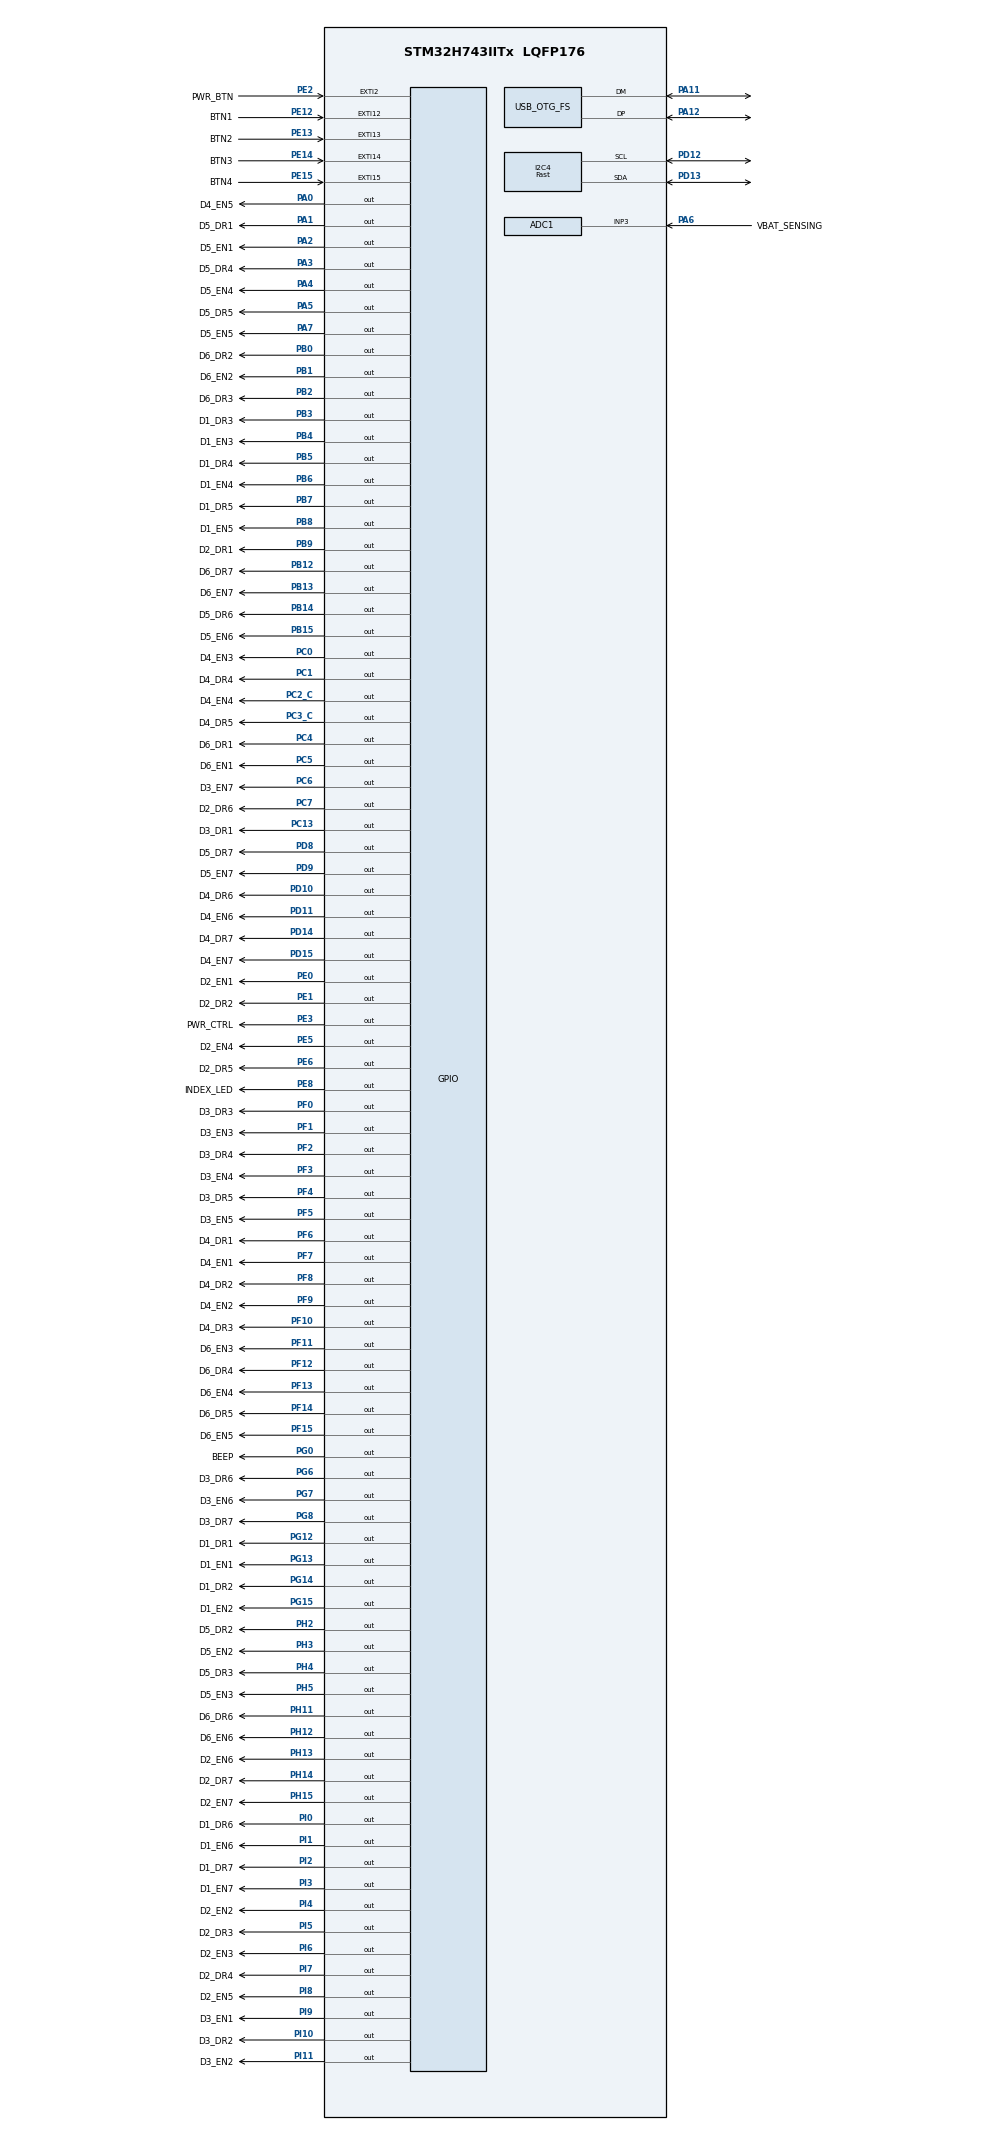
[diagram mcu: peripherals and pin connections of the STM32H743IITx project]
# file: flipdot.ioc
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ADC1.Channel-0\#ChannelRegularConversion=ADC_CHANNEL_3
ADC1.NbrOfConversionFlag=1
ADC1.OffsetNumber-0\#ChannelRegularConversion=ADC_OFFSET_NONE
ADC1.OffsetSignedSaturation-0\#ChannelRegularConversion=DISABLE
ADC1.Rank-0\#ChannelRegularConversion=1
ADC1.SamplingTime-0\#ChannelRegularConversion=ADC_SAMPLETIME_810CYCLES_5
ADC1.master=1
CORTEX_M7.AccessPermission_S-Cortex_Memory_Protection_Unit_Region1_Settings_S=MPU_REGION_FULL_ACCESS
CORTEX_M7.AccessPermission_Spec=MPU_REGION_FULL_ACCESS
CORTEX_M7.BaseAddress_S-Cortex_Memory_Protection_Unit_Region1_Settings_S=0x0
CORTEX_M7.BaseAddress_Spec=0x24000000
CORTEX_M7.Enable_S-Cortex_Memory_Protection_Unit_Region1_Settings_S=MPU_REGION_ENABLE
CORTEX_M7.IsCacheable_Spec=MPU_ACCESS_CACHEABLE
CORTEX_M7.Size_S-Cortex_Memory_Protection_Unit_Region1_Settings_S=MPU_REGION_SIZE_32MB
CORTEX_M7.Size_Spec=MPU_REGION_SIZE_512KB
CORTEX_M7.SubRegionDisable_Spec=0x00
CORTEX_M7.default_mode_Activation=1
Dma.ADC1.0.Direction=DMA_PERIPH_TO_MEMORY
Dma.ADC1.0.EventEnable=DISABLE
Dma.ADC1.0.FIFOMode=DMA_FIFOMODE_DISABLE
Dma.ADC1.0.Instance=DMA1_Stream0
Dma.ADC1.0.MemDataAlignment=DMA_MDATAALIGN_HALFWORD
Dma.ADC1.0.MemInc=DMA_MINC_ENABLE
Dma.ADC1.0.Mode=DMA_CIRCULAR
Dma.ADC1.0.PeriphDataAlignment=DMA_PDATAALIGN_HALFWORD
Dma.ADC1.0.PeriphInc=DMA_PINC_DISABLE
Dma.ADC1.0.Polarity=HAL_DMAMUX_REQ_GEN_RISING
Dma.ADC1.0.Priority=DMA_PRIORITY_LOW
Dma.ADC1.0.RequestNumber=1
Dma.ADC1.0.SignalID=NONE
Dma.ADC1.0.SyncEnable=DISABLE
Dma.ADC1.0.SyncPolarity=HAL_DMAMUX_SYNC_NO_EVENT
Dma.ADC1.0.SyncRequestNumber=1
Dma.ADC1.0.SyncSignalID=NONE
Dma.Request0=ADC1
FREERTOS.Queues01=button_queue,16,uint16_t,0,Dynamic,NULL,NULL
FREERTOS.Tasks01=defaultTask,24,256,StartDefaultTask,Default,NULL,Dynamic,NULL,NULL;buttonTask,24,1024,button_task,Default,NULL,Dynamic,NULL,NULL
FREERTOS.configUSE_NEWLIB_REENTRANT=1
I2C4.I2C_Speed_Mode=I2C_Fast
I2C4.Timing=0x00B03FDB
Mcu.Family=STM32H7
Mcu.Name=STM32H743IITx
Mcu.Package=LQFP176
NVIC.ADC_IRQn=true\:5\:0\:false\:false\:true\:true\:true\:true\:true
NVIC.DMA1_Stream0_IRQn=true\:5\:0\:false\:false\:true\:true\:false\:true\:true
NVIC.EXTI15_10_IRQn=true\:5\:0\:false\:false\:true\:true\:true\:true\:true
NVIC.EXTI2_IRQn=true\:5\:0\:false\:false\:true\:true\:true\:true\:true
NVIC.OTG_FS_IRQn=true\:5\:0\:false\:false\:true\:true\:false\:true\:true
NVIC.PriorityGroup=NVIC_PRIORITYGROUP_4
NVIC.TIM2_IRQn=true\:15\:0\:false\:false\:true\:false\:false\:true\:true
NVIC.TimeBase=TIM2_IRQn
NVIC.TimeBaseIP=TIM2
PA0.GPIO_Label=D4_EN5
PA0.GPIO_PuPd=GPIO_PULLDOWN
PA0.GPIO_Speed=GPIO_SPEED_FREQ_VERY_HIGH
PA0.Signal=GPIO_Output
PA1.GPIO_Label=D5_DR1
PA1.GPIO_PuPd=GPIO_PULLDOWN
PA1.GPIO_Speed=GPIO_SPEED_FREQ_VERY_HIGH
PA1.Signal=GPIO_Output
PA11.Mode=Device_Only
PA11.Signal=USB_OTG_FS_DM
PA12.Mode=Device_Only
PA12.Signal=USB_OTG_FS_DP
PA13\ (JTMS/SWDIO).Mode=Serial_Wire
PA13\ (JTMS/SWDIO).Signal=DEBUG_JTMS-SWDIO
PA14\ (JTCK/SWCLK).Mode=Serial_Wire
PA14\ (JTCK/SWCLK).Signal=DEBUG_JTCK-SWCLK
PA2.GPIO_Label=D5_EN1
PA2.GPIO_PuPd=GPIO_PULLDOWN
PA2.GPIO_Speed=GPIO_SPEED_FREQ_VERY_HIGH
PA2.Signal=GPIO_Output
PA3.GPIO_Label=D5_DR4
PA3.GPIO_PuPd=GPIO_PULLDOWN
PA3.GPIO_Speed=GPIO_SPEED_FREQ_VERY_HIGH
PA3.Signal=GPIO_Output
PA4.GPIO_Label=D5_EN4
PA4.GPIO_PuPd=GPIO_PULLDOWN
PA4.GPIO_Speed=GPIO_SPEED_FREQ_VERY_HIGH
PA4.Signal=GPIO_Output
PA5.GPIO_Label=D5_DR5
PA5.GPIO_PuPd=GPIO_PULLDOWN
PA5.GPIO_Speed=GPIO_SPEED_FREQ_VERY_HIGH
PA5.Signal=GPIO_Output
PA6.GPIO_Label=VBAT_SENSING
PA6.Signal=ADCx_INP3
PA7.GPIO_Label=D5_EN5
PA7.GPIO_PuPd=GPIO_PULLDOWN
PA7.GPIO_Speed=GPIO_SPEED_FREQ_VERY_HIGH
PA7.Signal=GPIO_Output
PB0.GPIO_Label=D6_DR2
PB0.GPIO_PuPd=GPIO_PULLDOWN
PB0.GPIO_Speed=GPIO_SPEED_FREQ_VERY_HIGH
PB0.Signal=GPIO_Output
PB1.GPIO_Label=D6_EN2
PB1.GPIO_PuPd=GPIO_PULLDOWN
PB1.GPIO_Speed=GPIO_SPEED_FREQ_VERY_HIGH
PB1.Signal=GPIO_Output
PB12.GPIO_Label=D6_DR7
PB12.GPIO_PuPd=GPIO_PULLDOWN
PB12.GPIO_Speed=GPIO_SPEED_FREQ_VERY_HIGH
PB12.Signal=GPIO_Output
PB13.GPIO_Label=D6_EN7
PB13.GPIO_PuPd=GPIO_PULLDOWN
PB13.GPIO_Speed=GPIO_SPEED_FREQ_VERY_HIGH
PB13.Signal=GPIO_Output
PB14.GPIO_Label=D5_DR6
PB14.GPIO_PuPd=GPIO_PULLDOWN
PB14.GPIO_Speed=GPIO_SPEED_FREQ_VERY_HIGH
PB14.Signal=GPIO_Output
PB15.GPIO_Label=D5_EN6
PB15.GPIO_PuPd=GPIO_PULLDOWN
PB15.GPIO_Speed=GPIO_SPEED_FREQ_VERY_HIGH
PB15.Signal=GPIO_Output
PB2.GPIO_Label=D6_DR3
PB2.GPIO_PuPd=GPIO_PULLDOWN
PB2.GPIO_Speed=GPIO_SPEED_FREQ_VERY_HIGH
PB2.Signal=GPIO_Output
PB3\ (JTDO/TRACESWO).GPIO_Label=D1_DR3
PB3\ (JTDO/TRACESWO).GPIO_PuPd=GPIO_PULLDOWN
PB3\ (JTDO/TRACESWO).GPIO_Speed=GPIO_SPEED_FREQ_VERY_HIGH
PB3\ (JTDO/TRACESWO).Signal=GPIO_Output
PB4\ (NJTRST).GPIO_Label=D1_EN3
PB4\ (NJTRST).GPIO_PuPd=GPIO_PULLDOWN
PB4\ (NJTRST).GPIO_Speed=GPIO_SPEED_FREQ_VERY_HIGH
PB4\ (NJTRST).Signal=GPIO_Output
PB5.GPIO_Label=D1_DR4
PB5.GPIO_PuPd=GPIO_PULLDOWN
PB5.GPIO_Speed=GPIO_SPEED_FREQ_VERY_HIGH
PB5.Signal=GPIO_Output
PB6.GPIO_Label=D1_EN4
PB6.GPIO_PuPd=GPIO_PULLDOWN
PB6.GPIO_Speed=GPIO_SPEED_FREQ_VERY_HIGH
PB6.Signal=GPIO_Output
PB7.GPIO_Label=D1_DR5
PB7.GPIO_PuPd=GPIO_PULLDOWN
PB7.GPIO_Speed=GPIO_SPEED_FREQ_VERY_HIGH
PB7.Signal=GPIO_Output
PB8.GPIO_Label=D1_EN5
PB8.GPIO_PuPd=GPIO_PULLDOWN
PB8.GPIO_Speed=GPIO_SPEED_FREQ_VERY_HIGH
PB8.Signal=GPIO_Output
PB9.GPIO_Label=D2_DR1
PB9.GPIO_PuPd=GPIO_PULLDOWN
PB9.GPIO_Speed=GPIO_SPEED_FREQ_VERY_HIGH
PB9.Signal=GPIO_Output
PC0.GPIO_Label=D4_EN3
PC0.GPIO_PuPd=GPIO_PULLDOWN
PC0.GPIO_Speed=GPIO_SPEED_FREQ_VERY_HIGH
PC0.Signal=GPIO_Output
PC1.GPIO_Label=D4_DR4
PC1.GPIO_PuPd=GPIO_PULLDOWN
PC1.GPIO_Speed=GPIO_SPEED_FREQ_VERY_HIGH
PC1.Signal=GPIO_Output
PC13.GPIO_Label=D3_DR1
PC13.GPIO_PuPd=GPIO_PULLDOWN
PC13.Signal=GPIO_Output
PC14-OSC32_IN\ (OSC32_IN).Mode=LSE-External-Oscillator
PC14-OSC32_IN\ (OSC32_IN).Signal=RCC_OSC32_IN
PC15-OSC32_OUT\ (OSC32_OUT).Mode=LSE-External-Oscillator
PC15-OSC32_OUT\ (OSC32_OUT).Signal=RCC_OSC32_OUT
PC2_C.GPIO_Label=D4_EN4
PC2_C.GPIO_PuPd=GPIO_PULLDOWN
PC2_C.GPIO_Speed=GPIO_SPEED_FREQ_VERY_HIGH
PC2_C.Signal=GPIO_Output
PC3_C.GPIO_Label=D4_DR5
PC3_C.GPIO_PuPd=GPIO_PULLDOWN
PC3_C.GPIO_Speed=GPIO_SPEED_FREQ_VERY_HIGH
PC3_C.Signal=GPIO_Output
PC4.GPIO_Label=D6_DR1
PC4.GPIO_PuPd=GPIO_PULLDOWN
PC4.GPIO_Speed=GPIO_SPEED_FREQ_VERY_HIGH
PC4.Signal=GPIO_Output
PC5.GPIO_Label=D6_EN1
PC5.GPIO_PuPd=GPIO_PULLDOWN
PC5.GPIO_Speed=GPIO_SPEED_FREQ_VERY_HIGH
PC5.Signal=GPIO_Output
PC6.GPIO_Label=D3_EN7
PC6.GPIO_PuPd=GPIO_PULLDOWN
PC6.GPIO_Speed=GPIO_SPEED_FREQ_VERY_HIGH
PC6.Signal=GPIO_Output
PC7.GPIO_Label=D2_DR6
PC7.GPIO_PuPd=GPIO_PULLDOWN
PC7.GPIO_Speed=GPIO_SPEED_FREQ_VERY_HIGH
PC7.Signal=GPIO_Output
PD10.GPIO_Label=D4_DR6
PD10.GPIO_PuPd=GPIO_PULLDOWN
PD10.GPIO_Speed=GPIO_SPEED_FREQ_VERY_HIGH
PD10.Signal=GPIO_Output
PD11.GPIO_Label=D4_EN6
PD11.GPIO_PuPd=GPIO_PULLDOWN
PD11.GPIO_Speed=GPIO_SPEED_FREQ_VERY_HIGH
PD11.Signal=GPIO_Output
PD12.Mode=I2C
PD12.Signal=I2C4_SCL
PD13.Mode=I2C
PD13.Signal=I2C4_SDA
PD14.GPIO_Label=D4_DR7
PD14.GPIO_PuPd=GPIO_PULLDOWN
PD14.GPIO_Speed=GPIO_SPEED_FREQ_VERY_HIGH
PD14.Signal=GPIO_Output
PD15.GPIO_Label=D4_EN7
PD15.GPIO_PuPd=GPIO_PULLDOWN
PD15.GPIO_Speed=GPIO_SPEED_FREQ_VERY_HIGH
PD15.Signal=GPIO_Output
PD8.GPIO_Label=D5_DR7
PD8.GPIO_PuPd=GPIO_PULLDOWN
PD8.GPIO_Speed=GPIO_SPEED_FREQ_VERY_HIGH
PD8.Signal=GPIO_Output
PD9.GPIO_Label=D5_EN7
PD9.GPIO_PuPd=GPIO_PULLDOWN
PD9.GPIO_Speed=GPIO_SPEED_FREQ_VERY_HIGH
PD9.Signal=GPIO_Output
PE0.GPIO_Label=D2_EN1
PE0.GPIO_PuPd=GPIO_PULLDOWN
PE0.GPIO_Speed=GPIO_SPEED_FREQ_VERY_HIGH
PE0.Signal=GPIO_Output
PE1.GPIO_Label=D2_DR2
PE1.GPIO_PuPd=GPIO_PULLDOWN
PE1.GPIO_Speed=GPIO_SPEED_FREQ_VERY_HIGH
PE1.Signal=GPIO_Output
PE12.GPIO_Label=BTN1
PE12.GPIO_ModeDefaultEXTI=GPIO_MODE_IT_RISING_FALLING
PE12.GPIO_PuPd=GPIO_PULLDOWN
PE12.Signal=GPXTI12
PE13.GPIO_Label=BTN2
PE13.GPIO_ModeDefaultEXTI=GPIO_MODE_IT_RISING_FALLING
PE13.GPIO_PuPd=GPIO_PULLDOWN
PE13.Signal=GPXTI13
PE14.GPIO_Label=BTN3
PE14.GPIO_ModeDefaultEXTI=GPIO_MODE_IT_RISING_FALLING
PE14.GPIO_PuPd=GPIO_PULLDOWN
PE14.Signal=GPXTI14
PE15.GPIO_Label=BTN4
PE15.GPIO_ModeDefaultEXTI=GPIO_MODE_IT_RISING_FALLING
PE15.GPIO_PuPd=GPIO_PULLDOWN
PE15.Signal=GPXTI15
PE2.GPIO_Label=PWR_BTN
PE2.GPIO_ModeDefaultEXTI=GPIO_MODE_IT_RISING_FALLING
PE2.GPIO_PuPd=GPIO_NOPULL
PE2.Signal=GPXTI2
PE3.GPIO_Label=PWR_CTRL
PE3.Signal=GPIO_Output
PE5.GPIO_Label=D2_EN4
PE5.GPIO_PuPd=GPIO_PULLDOWN
PE5.GPIO_Speed=GPIO_SPEED_FREQ_VERY_HIGH
PE5.Signal=GPIO_Output
PE6.GPIO_Label=D2_DR5
PE6.GPIO_PuPd=GPIO_PULLDOWN
PE6.GPIO_Speed=GPIO_SPEED_FREQ_VERY_HIGH
PE6.Signal=GPIO_Output
PE8.GPIO_Label=INDEX_LED
PE8.GPIO_PuPd=GPIO_PULLDOWN
PE8.Signal=GPIO_Output
PF0.GPIO_Label=D3_DR3
PF0.GPIO_PuPd=GPIO_PULLDOWN
PF0.GPIO_Speed=GPIO_SPEED_FREQ_VERY_HIGH
PF0.Signal=GPIO_Output
PF1.GPIO_Label=D3_EN3
PF1.GPIO_PuPd=GPIO_PULLDOWN
PF1.GPIO_Speed=GPIO_SPEED_FREQ_VERY_HIGH
PF1.Signal=GPIO_Output
PF10.GPIO_Label=D4_DR3
PF10.GPIO_PuPd=GPIO_PULLDOWN
PF10.GPIO_Speed=GPIO_SPEED_FREQ_VERY_HIGH
PF10.Signal=GPIO_Output
PF11.GPIO_Label=D6_EN3
PF11.GPIO_PuPd=GPIO_PULLDOWN
PF11.GPIO_Speed=GPIO_SPEED_FREQ_VERY_HIGH
PF11.Signal=GPIO_Output
PF12.GPIO_Label=D6_DR4
PF12.GPIO_PuPd=GPIO_PULLDOWN
PF12.GPIO_Speed=GPIO_SPEED_FREQ_VERY_HIGH
PF12.Signal=GPIO_Output
PF13.GPIO_Label=D6_EN4
PF13.GPIO_PuPd=GPIO_PULLDOWN
PF13.GPIO_Speed=GPIO_SPEED_FREQ_VERY_HIGH
PF13.Signal=GPIO_Output
PF14.GPIO_Label=D6_DR5
PF14.GPIO_PuPd=GPIO_PULLDOWN
PF14.GPIO_Speed=GPIO_SPEED_FREQ_VERY_HIGH
PF14.Signal=GPIO_Output
PF15.GPIO_Label=D6_EN5
PF15.GPIO_PuPd=GPIO_PULLDOWN
PF15.GPIO_Speed=GPIO_SPEED_FREQ_VERY_HIGH
PF15.Signal=GPIO_Output
PF2.GPIO_Label=D3_DR4
PF2.GPIO_PuPd=GPIO_PULLDOWN
PF2.GPIO_Speed=GPIO_SPEED_FREQ_VERY_HIGH
PF2.Signal=GPIO_Output
PF3.GPIO_Label=D3_EN4
PF3.GPIO_PuPd=GPIO_PULLDOWN
PF3.GPIO_Speed=GPIO_SPEED_FREQ_VERY_HIGH
PF3.Signal=GPIO_Output
PF4.GPIO_Label=D3_DR5
PF4.GPIO_PuPd=GPIO_PULLDOWN
PF4.GPIO_Speed=GPIO_SPEED_FREQ_VERY_HIGH
PF4.Signal=GPIO_Output
PF5.GPIO_Label=D3_EN5
PF5.GPIO_PuPd=GPIO_PULLDOWN
PF5.GPIO_Speed=GPIO_SPEED_FREQ_VERY_HIGH
PF5.Signal=GPIO_Output
PF6.GPIO_Label=D4_DR1
PF6.GPIO_PuPd=GPIO_PULLDOWN
PF6.GPIO_Speed=GPIO_SPEED_FREQ_VERY_HIGH
PF6.Signal=GPIO_Output
PF7.GPIO_Label=D4_EN1
PF7.GPIO_PuPd=GPIO_PULLDOWN
PF7.GPIO_Speed=GPIO_SPEED_FREQ_VERY_HIGH
PF7.Signal=GPIO_Output
PF8.GPIO_Label=D4_DR2
PF8.GPIO_PuPd=GPIO_PULLDOWN
PF8.GPIO_Speed=GPIO_SPEED_FREQ_VERY_HIGH
PF8.Signal=GPIO_Output
PF9.GPIO_Label=D4_EN2
PF9.GPIO_PuPd=GPIO_PULLDOWN
PF9.GPIO_Speed=GPIO_SPEED_FREQ_VERY_HIGH
PF9.Signal=GPIO_Output
PG0.GPIO_Label=BEEP
PG0.Signal=GPIO_Output
PG12.GPIO_Label=D1_DR1
PG12.GPIO_PuPd=GPIO_PULLDOWN
PG12.GPIO_Speed=GPIO_SPEED_FREQ_VERY_HIGH
PG12.Signal=GPIO_Output
PG13.GPIO_Label=D1_EN1
PG13.GPIO_PuPd=GPIO_PULLDOWN
PG13.GPIO_Speed=GPIO_SPEED_FREQ_VERY_HIGH
PG13.Signal=GPIO_Output
PG14.GPIO_Label=D1_DR2
PG14.GPIO_PuPd=GPIO_PULLDOWN
PG14.GPIO_Speed=GPIO_SPEED_FREQ_VERY_HIGH
PG14.Signal=GPIO_Output
PG15.GPIO_Label=D1_EN2
PG15.GPIO_PuPd=GPIO_PULLDOWN
PG15.GPIO_Speed=GPIO_SPEED_FREQ_VERY_HIGH
PG15.Signal=GPIO_Output
PG6.GPIO_Label=D3_DR6
PG6.GPIO_PuPd=GPIO_PULLDOWN
PG6.GPIO_Speed=GPIO_SPEED_FREQ_VERY_HIGH
PG6.Signal=GPIO_Output
PG7.GPIO_Label=D3_EN6
PG7.GPIO_PuPd=GPIO_PULLDOWN
PG7.GPIO_Speed=GPIO_SPEED_FREQ_VERY_HIGH
PG7.Signal=GPIO_Output
PG8.GPIO_Label=D3_DR7
PG8.GPIO_PuPd=GPIO_PULLDOWN
PG8.GPIO_Speed=GPIO_SPEED_FREQ_VERY_HIGH
PG8.Signal=GPIO_Output
PH0-OSC_IN\ (PH0).Mode=HSE-External-Oscillator
PH0-OSC_IN\ (PH0).Signal=RCC_OSC_IN
PH1-OSC_OUT\ (PH1).Mode=HSE-External-Oscillator
PH1-OSC_OUT\ (PH1).Signal=RCC_OSC_OUT
PH11.GPIO_Label=D6_DR6
PH11.GPIO_PuPd=GPIO_PULLDOWN
PH11.GPIO_Speed=GPIO_SPEED_FREQ_VERY_HIGH
PH11.Signal=GPIO_Output
PH12.GPIO_Label=D6_EN6
PH12.GPIO_PuPd=GPIO_PULLDOWN
PH12.GPIO_Speed=GPIO_SPEED_FREQ_VERY_HIGH
PH12.Signal=GPIO_Output
PH13.GPIO_Label=D2_EN6
PH13.GPIO_PuPd=GPIO_PULLDOWN
PH13.GPIO_Speed=GPIO_SPEED_FREQ_VERY_HIGH
PH13.Signal=GPIO_Output
PH14.GPIO_Label=D2_DR7
PH14.GPIO_PuPd=GPIO_PULLDOWN
PH14.GPIO_Speed=GPIO_SPEED_FREQ_VERY_HIGH
PH14.Signal=GPIO_Output
PH15.GPIO_Label=D2_EN7
PH15.GPIO_PuPd=GPIO_PULLDOWN
PH15.GPIO_Speed=GPIO_SPEED_FREQ_VERY_HIGH
PH15.Signal=GPIO_Output
PH2.GPIO_Label=D5_DR2
PH2.GPIO_PuPd=GPIO_PULLDOWN
PH2.GPIO_Speed=GPIO_SPEED_FREQ_VERY_HIGH
PH2.Signal=GPIO_Output
PH3.GPIO_Label=D5_EN2
PH3.GPIO_PuPd=GPIO_PULLDOWN
PH3.GPIO_Speed=GPIO_SPEED_FREQ_VERY_HIGH
PH3.Signal=GPIO_Output
PH4.GPIO_Label=D5_DR3
PH4.GPIO_PuPd=GPIO_PULLDOWN
PH4.GPIO_Speed=GPIO_SPEED_FREQ_VERY_HIGH
PH4.Signal=GPIO_Output
PH5.GPIO_Label=D5_EN3
PH5.GPIO_PuPd=GPIO_PULLDOWN
PH5.GPIO_Speed=GPIO_SPEED_FREQ_VERY_HIGH
PH5.Signal=GPIO_Output
PI0.GPIO_Label=D1_DR6
PI0.GPIO_PuPd=GPIO_PULLDOWN
PI0.GPIO_Speed=GPIO_SPEED_FREQ_VERY_HIGH
PI0.Signal=GPIO_Output
PI1.GPIO_Label=D1_EN6
PI1.GPIO_PuPd=GPIO_PULLDOWN
PI1.GPIO_Speed=GPIO_SPEED_FREQ_VERY_HIGH
PI1.Signal=GPIO_Output
PI10.GPIO_Label=D3_DR2
PI10.GPIO_PuPd=GPIO_PULLDOWN
PI10.GPIO_Speed=GPIO_SPEED_FREQ_VERY_HIGH
PI10.Signal=GPIO_Output
PI11.GPIO_Label=D3_EN2
PI11.GPIO_PuPd=GPIO_PULLDOWN
PI11.GPIO_Speed=GPIO_SPEED_FREQ_VERY_HIGH
PI11.Signal=GPIO_Output
PI2.GPIO_Label=D1_DR7
PI2.GPIO_PuPd=GPIO_PULLDOWN
PI2.GPIO_Speed=GPIO_SPEED_FREQ_VERY_HIGH
PI2.Signal=GPIO_Output
PI3.GPIO_Label=D1_EN7
PI3.GPIO_PuPd=GPIO_PULLDOWN
PI3.GPIO_Speed=GPIO_SPEED_FREQ_VERY_HIGH
PI3.Signal=GPIO_Output
PI4.GPIO_Label=D2_EN2
PI4.GPIO_PuPd=GPIO_PULLDOWN
PI4.GPIO_Speed=GPIO_SPEED_FREQ_VERY_HIGH
PI4.Signal=GPIO_Output
PI5.GPIO_Label=D2_DR3
PI5.GPIO_PuPd=GPIO_PULLDOWN
PI5.GPIO_Speed=GPIO_SPEED_FREQ_VERY_HIGH
PI5.Signal=GPIO_Output
PI6.GPIO_Label=D2_EN3
PI6.GPIO_PuPd=GPIO_PULLDOWN
PI6.GPIO_Speed=GPIO_SPEED_FREQ_VERY_HIGH
PI6.Signal=GPIO_Output
PI7.GPIO_Label=D2_DR4
PI7.GPIO_PuPd=GPIO_PULLDOWN
PI7.GPIO_Speed=GPIO_SPEED_FREQ_VERY_HIGH
PI7.Signal=GPIO_Output
PI8.GPIO_Label=D2_EN5
PI8.GPIO_PuPd=GPIO_PULLDOWN
PI8.Signal=GPIO_Output
PI9.GPIO_Label=D3_EN1
PI9.GPIO_PuPd=GPIO_PULLDOWN
PI9.GPIO_Speed=GPIO_SPEED_FREQ_VERY_HIGH
PI9.Signal=GPIO_Output
ProjectManager.HeapSize=0x1000
ProjectManager.StackSize=0x1000
ProjectManager.TargetToolchain=CMake
RCC.ADCFreq_Value=75000000
RCC.APB1Freq_Value=120000000
RCC.APB2Freq_Value=120000000
RCC.APB3Freq_Value=120000000
RCC.APB4Freq_Value=120000000
RCC.CortexFreq_Value=480000000
RCC.D1PPRE=RCC_APB3_DIV2
RCC.D2PPRE1=RCC_APB1_DIV2
RCC.D2PPRE2=RCC_APB2_DIV2
RCC.D3PPRE=RCC_APB4_DIV2
RCC.DIVM1=5
RCC.DIVM2=2
RCC.DIVN1=192
RCC.DIVN2=12
RCC.HCLKFreq_Value=240000000
RCC.HPRE=RCC_HCLK_DIV2
RCC.PLL2FRACN=0
RCC.PLL3FRACN=0
RCC.PLLFRACN=0
RCC.PLLSourceVirtual=RCC_PLLSOURCE_HSE
RCC.SYSCLKFreq_VALUE=480000000
RCC.SYSCLKSource=RCC_SYSCLKSOURCE_PLLCLK
RCC.USBCLockSelection=RCC_USBCLKSOURCE_HSI48
RCC.USBFreq_Value=48000000
SH.ADCx_INP3.0=ADC1_INP3,IN3-Single-Ended
USB_DEVICE.CLASS_NAME_FS=CDC
USB_DEVICE.VirtualMode-CDC_FS=Cdc
USB_DEVICE.VirtualModeFS=Cdc_FS
USB_OTG_FS.VirtualMode=Device_Only
VP_FREERTOS_VS_CMSIS_V2.Mode=CMSIS_V2
VP_MEMORYMAP_VS_MEMORYMAP.Mode=CurAppReg
VP_RCC_LSE.Mode=CRS SYNC Source LSE
VP_SYS_VS_tim2.Mode=TIM2
VP_USB_DEVICE_VS_USB_DEVICE_CDC_FS.Mode=CDC_FS
board=custom

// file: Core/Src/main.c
/* USER CODE BEGIN Header */
/**
 ******************************************************************************
 * @file           : main.c
 * @brief          : Main program body
 ******************************************************************************
 * @attention
 *
 * Copyright (c) 2025 STMicroelectronics.
 * All rights reserved.
 *
 * This software is licensed under terms that can be found in the LICENSE file
 * in the root directory of this software component.
 * If no LICENSE file comes with this software, it is provided AS-IS.
 *
 ******************************************************************************
 */
/* USER CODE END Header */
#include "main.h"
#include "cmsis_os.h"
#include "adc.h"
#include "dma.h"
#include "i2c.h"
#include "memorymap.h"
#include "usb_device.h"
#include "gpio.h"

void SystemClock_Config(void);
static void MPU_Config(void);
void MX_FREERTOS_Init(void);

int main(void)
{

  /* MPU Configuration--------------------------------------------------------*/
  MPU_Config();

  /* MCU Configuration--------------------------------------------------------*/

  /* Reset of all peripherals, Initializes the Flash interface and the Systick. */
  HAL_Init();

  /* Configure the system clock */
  SystemClock_Config();

  /* Initialize all configured peripherals */
  MX_GPIO_Init();
  MX_DMA_Init();
  MX_I2C4_Init();
  MX_ADC1_Init();
  /* USER CODE BEGIN 2 */
  PWR_CTRL(1);
  /* USER CODE END 2 */

  /* Init scheduler */
  osKernelInitialize();

  /* Call init function for freertos objects (in cmsis_os2.c) */
  MX_FREERTOS_Init();

  /* Start scheduler */
  osKernelStart();

  /* We should never get here as control is now taken by the scheduler */

  /* Infinite loop */
  while (1)
  {

  }
}

void SystemClock_Config(void)
{
  RCC_OscInitTypeDef RCC_OscInitStruct = {0};
  RCC_ClkInitTypeDef RCC_ClkInitStruct = {0};
  RCC_CRSInitTypeDef RCC_CRSInitStruct = {0};

  /** Supply configuration update enable
  */
  HAL_PWREx_ConfigSupply(PWR_LDO_SUPPLY);

  /** Configure the main internal regulator output voltage
  */
  __HAL_PWR_VOLTAGESCALING_CONFIG(PWR_REGULATOR_VOLTAGE_SCALE0);

  while(!__HAL_PWR_GET_FLAG(PWR_FLAG_VOSRDY)) {}

  /** Configure LSE Drive Capability
  */
  HAL_PWR_EnableBkUpAccess();
  __HAL_RCC_LSEDRIVE_CONFIG(RCC_LSEDRIVE_LOW);

  /** Initializes the RCC Oscillators according to the specified parameters
  * in the RCC_OscInitTypeDef structure.
  */
  RCC_OscInitStruct.OscillatorType = RCC_OSCILLATORTYPE_HSI48|RCC_OSCILLATORTYPE_HSE
                              |RCC_OSCILLATORTYPE_LSE;
  RCC_OscInitStruct.HSEState = RCC_HSE_ON;
  RCC_OscInitStruct.LSEState = RCC_LSE_ON;
  RCC_OscInitStruct.HSI48State = RCC_HSI48_ON;
  RCC_OscInitStruct.PLL.PLLState = RCC_PLL_ON;
  RCC_OscInitStruct.PLL.PLLSource = RCC_PLLSOURCE_HSE;
  RCC_OscInitStruct.PLL.PLLM = 5;
  RCC_OscInitStruct.PLL.PLLN = 192;
  RCC_OscInitStruct.PLL.PLLP = 2;
  RCC_OscInitStruct.PLL.PLLQ = 2;
  RCC_OscInitStruct.PLL.PLLR = 2;
  RCC_OscInitStruct.PLL.PLLRGE = RCC_PLL1VCIRANGE_2;
  RCC_OscInitStruct.PLL.PLLVCOSEL = RCC_PLL1VCOWIDE;
  RCC_OscInitStruct.PLL.PLLFRACN = 0;
  if (HAL_RCC_OscConfig(&RCC_OscInitStruct) != HAL_OK)
  {
    Error_Handler();
  }

  /** Initializes the CPU, AHB and APB buses clocks
  */
  RCC_ClkInitStruct.ClockType = RCC_CLOCKTYPE_HCLK|RCC_CLOCKTYPE_SYSCLK
                              |RCC_CLOCKTYPE_PCLK1|RCC_CLOCKTYPE_PCLK2
                              |RCC_CLOCKTYPE_D3PCLK1|RCC_CLOCKTYPE_D1PCLK1;
  RCC_ClkInitStruct.SYSCLKSource = RCC_SYSCLKSOURCE_PLLCLK;
  RCC_ClkInitStruct.SYSCLKDivider = RCC_SYSCLK_DIV1;
  RCC_ClkInitStruct.AHBCLKDivider = RCC_HCLK_DIV2;
  RCC_ClkInitStruct.APB3CLKDivider = RCC_APB3_DIV2;
  RCC_ClkInitStruct.APB1CLKDivider = RCC_APB1_DIV2;
  RCC_ClkInitStruct.APB2CLKDivider = RCC_APB2_DIV2;
  RCC_ClkInitStruct.APB4CLKDivider = RCC_APB4_DIV2;

  if (HAL_RCC_ClockConfig(&RCC_ClkInitStruct, FLASH_LATENCY_4) != HAL_OK)
  {
    Error_Handler();
  }

  /** Enable the SYSCFG APB clock
  */
  __HAL_RCC_CRS_CLK_ENABLE();

  /** Configures CRS
  */
  RCC_CRSInitStruct.Prescaler = RCC_CRS_SYNC_DIV1;
  RCC_CRSInitStruct.Source = RCC_CRS_SYNC_SOURCE_LSE;
  RCC_CRSInitStruct.Polarity = RCC_CRS_SYNC_POLARITY_RISING;
  RCC_CRSInitStruct.ReloadValue = __HAL_RCC_CRS_RELOADVALUE_CALCULATE(48000000,32768);
  RCC_CRSInitStruct.ErrorLimitValue = 34;
  RCC_CRSInitStruct.HSI48CalibrationValue = 32;

  HAL_RCCEx_CRSConfig(&RCC_CRSInitStruct);
}

 /* MPU Configuration */

void MPU_Config(void)
{
  MPU_Region_InitTypeDef MPU_InitStruct = {0};

  /* Disables the MPU */
  HAL_MPU_Disable();

  /** Initializes and configures the Region and the memory to be protected
  */
  MPU_InitStruct.Enable = MPU_REGION_ENABLE;
  MPU_InitStruct.Number = MPU_REGION_NUMBER0;
  MPU_InitStruct.BaseAddress = 0x24000000;
  MPU_InitStruct.Size = MPU_REGION_SIZE_512KB;
  MPU_InitStruct.SubRegionDisable = 0x00;
  MPU_InitStruct.TypeExtField = MPU_TEX_LEVEL0;
  MPU_InitStruct.AccessPermission = MPU_REGION_FULL_ACCESS;
  MPU_InitStruct.DisableExec = MPU_INSTRUCTION_ACCESS_DISABLE;
  MPU_InitStruct.IsShareable = MPU_ACCESS_SHAREABLE;
  MPU_InitStruct.IsCacheable = MPU_ACCESS_CACHEABLE;
  MPU_InitStruct.IsBufferable = MPU_ACCESS_NOT_BUFFERABLE;

  HAL_MPU_ConfigRegion(&MPU_InitStruct);

  /** Initializes and configures the Region and the memory to be protected
  */
  MPU_InitStruct.Number = MPU_REGION_NUMBER1;
  MPU_InitStruct.BaseAddress = 0x0;
  MPU_InitStruct.Size = MPU_REGION_SIZE_32MB;
  MPU_InitStruct.SubRegionDisable = 0x0;
  MPU_InitStruct.DisableExec = MPU_INSTRUCTION_ACCESS_ENABLE;
  MPU_InitStruct.IsShareable = MPU_ACCESS_NOT_SHAREABLE;
  MPU_InitStruct.IsCacheable = MPU_ACCESS_NOT_CACHEABLE;

  HAL_MPU_ConfigRegion(&MPU_InitStruct);
  /* Enables the MPU */
  HAL_MPU_Enable(MPU_PRIVILEGED_DEFAULT);

}

void HAL_TIM_PeriodElapsedCallback(TIM_HandleTypeDef *htim)
{
  if (htim->Instance == TIM2) {
    HAL_IncTick();
  }
}

void Error_Handler(void)
{
  __disable_irq();
  while (1)
  {
  }
}

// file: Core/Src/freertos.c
/* USER CODE BEGIN Header */
/**
 ******************************************************************************
 * File Name          : freertos.c
 * Description        : Code for freertos applications
 ******************************************************************************
 * @attention
 *
 * Copyright (c) 2025 STMicroelectronics.
 * All rights reserved.
 *
 * This software is licensed under terms that can be found in the LICENSE file
 * in the root directory of this software component.
 * If no LICENSE file comes with this software, it is provided AS-IS.
 *
 ******************************************************************************
 */
/* USER CODE END Header */

#include "FreeRTOS.h"
#include "task.h"
#include "main.h"
#include "cmsis_os.h"

/* USER CODE BEGIN Includes */
#include "../../Components/Inc/flipdot_digit.h"
/* USER CODE END Includes */

/* USER CODE BEGIN Variables */
flipdot_digit_typdef *flipdot = NULL;
uint8_t pin1_state = 0;
/* USER CODE END Variables */
/* Definitions for defaultTask */
osThreadId_t defaultTaskHandle;
const osThreadAttr_t defaultTask_attributes = {
  .name = "defaultTask",
  .stack_size = 256 * 4,
  .priority = (osPriority_t) osPriorityNormal,
};
/* Definitions for buttonTask */
osThreadId_t buttonTaskHandle;
const osThreadAttr_t buttonTask_attributes = {
  .name = "buttonTask",
  .stack_size = 1024 * 4,
  .priority = (osPriority_t) osPriorityNormal,
};
/* Definitions for button_queue */
osMessageQueueId_t button_queueHandle;
const osMessageQueueAttr_t button_queue_attributes = {
  .name = "button_queue"
};

void StartDefaultTask(void *argument);
void button_task(void *argument);

extern void MX_USB_DEVICE_Init(void);
void MX_FREERTOS_Init(void); /* (MISRA C 2004 rule 8.1) */

void MX_FREERTOS_Init(void) {

  /* Create the queue(s) */
  /* creation of button_queue */
  button_queueHandle = osMessageQueueNew (16, sizeof(uint16_t), &button_queue_attributes);

  /* Create the thread(s) */
  /* creation of defaultTask */
  defaultTaskHandle = osThreadNew(StartDefaultTask, NULL, &defaultTask_attributes);

  /* creation of buttonTask */
  buttonTaskHandle = osThreadNew(button_task, NULL, &buttonTask_attributes);

}

void StartDefaultTask(void *argument)
{
  /* init code for USB_DEVICE */
  MX_USB_DEVICE_Init();
  /* USER CODE BEGIN StartDefaultTask */
  flipdot_digit_init();
  flipdot = get_flipdot_unit();
  /* Infinite loop */
  for (;;)
  {
    osDelay(1000);
  }
  /* USER CODE END StartDefaultTask */
}

void button_task(void *argument)
{
  /* USER CODE BEGIN button_task */
  char value[10] = {'0', '1', '2', '3', '4', '5', '6', '7', '8', '9'};
  uint8_t count = 0;
  /* Infinite loop */
  for (;;)
  {
    if (flipdot)
    {
      flipdot->flipdot_show_char(DIGIT_1, value[count]);
      // flipdot->flipdot_show_char(DIGIT_2, 0);
      // flipdot->flipdot_show_char(DIGIT_3, 0);
      // flipdot->flipdot_show_char(DIGIT_4, 0);
      // flipdot->flipdot_show_char(DIGIT_5, 0);
      // flipdot->flipdot_show_char(DIGIT_6, 0);
      count++;
      if (count == 10)
      {
        count = 0;
      }
    }
    pin1_state = HAL_GPIO_ReadPin(PWR_BTN_GPIO_Port, PWR_BTN_Pin);
    STUS_LED_TOGGLE;
    osDelay(1000);
  }
  /* USER CODE END button_task */
}

/* USER CODE BEGIN Application */
void HAL_GPIO_EXTI_Callback(uint16_t GPIO_Pin)
{
  switch (GPIO_Pin)
  {
  case BTN1_Pin:

    break;
  case BTN2_Pin:

    break;
  case BTN3_Pin:

    break;
  case BTN4_Pin:

    break;
  case PWR_BTN_Pin:

    break;
  }
}
/* USER CODE END Application */
